# COMPUTE_CLUSTER0_ECC_AGGR register map
Vendor: Texas Instruments
Peripheral module from a debugger description file (folder J7VCL).
Registers are 32-bit, access not given, reset 0x0 unless marked. A register's access mark holds for its fields unless they carry their own. Offsets are as the file gives them; lines under a group give offsets from that group; [hi:lo] are bit positions; {n}, {i} and the like mark numbered series; 'fields as' and 'values as' point back to an identical list; <NAME> marks a mode.

## COMPUTE_CLUSTER0_ECC_AGGR
0x00 GIC_ECC_AGGR_REV ro reset 0x66A0EA00 — IP revision register.
  [31:0] REV — TI internal data. Identifies revision of peripheral.
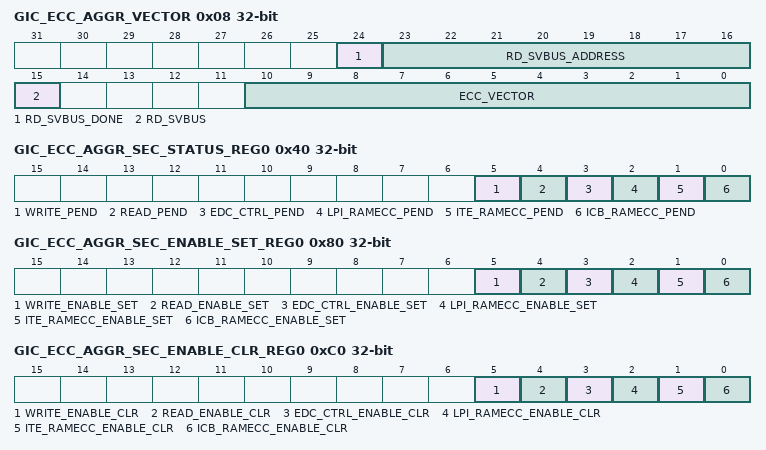
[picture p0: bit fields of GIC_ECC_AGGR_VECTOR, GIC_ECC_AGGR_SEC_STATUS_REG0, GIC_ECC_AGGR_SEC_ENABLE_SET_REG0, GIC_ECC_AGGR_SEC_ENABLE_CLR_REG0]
0x08 GIC_ECC_AGGR_VECTOR — ECC vector register.
  [24] RD_SVBUS_DONE — Status to indicate if read on serial VBUS is complete, write of any value will clear this bit. (access RW1C)
  [23:16] RD_SVBUS_ADDRESS rw — Read address
  [15] RD_SVBUS — Write 1 to trigger a read on the serial VBUS (access RW1S)
  [10:0] ECC_VECTOR rw — Value written to select the corresponding ECC RAM for control or status
0x0C GIC_ECC_AGGR_STAT ro reset 0x6 — Misc status register.
  [10:0] NUM_RAMS — Indicates the number of RAMs serviced by the ECC aggregator
0x3C GIC_ECC_AGGR_SEC_EOI_REG — EOI register. The EOI register is used to re-trigger the pulse interrupt signal to ensure that any nested interrupt events are serviced. The software interrupt handler must write to the EOI register at the end of the current interrupt processing routine, so that new events can re-trigger the pulse interrupt signal again. For level interrupt signals the EOI register is not functional and must not be used.
  [0] EOI_WR — EOI value (access RW1S)
0x40 GIC_ECC_AGGR_SEC_STATUS_REG0 — SEC interrupt status register 0.
  [5] WRITE_PEND — Interrupt pending status for write_pend (access RW1S)
  [4] READ_PEND — Interrupt pending status for read_pend (access RW1S)
  [3] EDC_CTRL_PEND — Interrupt pending status for edc_ctrl_pend (access RW1S)
  [2] LPI_RAMECC_PEND — Interrupt pending status for lpi_ramecc_pend (access RW1S)
  [1] ITE_RAMECC_PEND — Interrupt pending status for ite_ramecc_pend (access RW1S)
  [0] ICB_RAMECC_PEND — Interrupt pending status for icb_ramecc_pend (access RW1S)
0x80 GIC_ECC_AGGR_SEC_ENABLE_SET_REG0 — SEC interrupt enable set register 0.
  [5] WRITE_ENABLE_SET — Interrupt enable set for write_pend (access RW1S)
  [4] READ_ENABLE_SET — Interrupt enable set for read_pend (access RW1S)
  [3] EDC_CTRL_ENABLE_SET — Interrupt enable set for edc_ctrl_pend (access RW1S)
  [2] LPI_RAMECC_ENABLE_SET — Interrupt enable set for lpi_ramecc_pend (access RW1S)
  [1] ITE_RAMECC_ENABLE_SET — Interrupt enable set for ite_ramecc_pend (access RW1S)
  [0] ICB_RAMECC_ENABLE_SET — Interrupt enable set for icb_ramecc_pend (access RW1S)
0xC0 GIC_ECC_AGGR_SEC_ENABLE_CLR_REG0 — SEC interrupt enable clear register 0.
  [5] WRITE_ENABLE_CLR — Interrupt enable clear for write_pend (access RW1C)
  [4] READ_ENABLE_CLR — Interrupt enable clear for read_pend (access RW1C)
  [3] EDC_CTRL_ENABLE_CLR — Interrupt enable clear for edc_ctrl_pend (access RW1C)
  [2] LPI_RAMECC_ENABLE_CLR — Interrupt enable clear for lpi_ramecc_pend (access RW1C)
  [1] ITE_RAMECC_ENABLE_CLR — Interrupt enable clear for ite_ramecc_pend (access RW1C)
  [0] ICB_RAMECC_ENABLE_CLR — Interrupt enable clear for icb_ramecc_pend (access RW1C)
0x13C GIC_ECC_AGGR_DED_EOI_REG — DED EOI register. The EOI register is used to re-trigger the pulse interrupt signal to ensure that any nested interrupt events are serviced. The software interrupt handler must write to the EOI register at the end of the current interrupt processing routine, so that new events can re-trigger the pulse interrupt signal again. For level interrupt signals the EOI register is not functional and must not be used.
  [0] EOI_WR — EOI value (access RW1S)
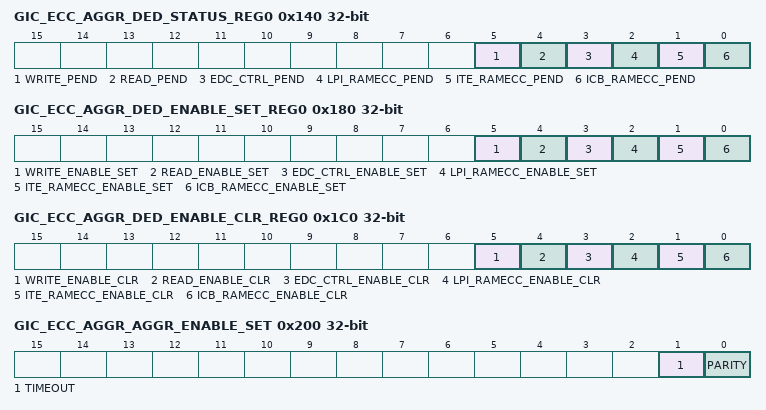
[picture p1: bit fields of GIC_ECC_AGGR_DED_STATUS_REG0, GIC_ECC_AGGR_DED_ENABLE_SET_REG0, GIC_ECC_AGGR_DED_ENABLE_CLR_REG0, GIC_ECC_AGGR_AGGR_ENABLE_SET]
0x140 GIC_ECC_AGGR_DED_STATUS_REG0 — DED interrupt status register 0.
  fields as GIC_ECC_AGGR_SEC_STATUS_REG0
0x180 GIC_ECC_AGGR_DED_ENABLE_SET_REG0 — DED interrupt enable set register 0.
  fields as GIC_ECC_AGGR_SEC_ENABLE_SET_REG0
0x1C0 GIC_ECC_AGGR_DED_ENABLE_CLR_REG0 — DED interrupt enable clear register 0.
  fields as GIC_ECC_AGGR_SEC_ENABLE_CLR_REG0
0x200 GIC_ECC_AGGR_AGGR_ENABLE_SET — AGGR interrupt enable set register.
  [1] TIMEOUT — Interrupt enable set for svbus timeout errors (access RW1S)
  [0] PARITY — Interrupt enable set for parity errors (access RW1S)
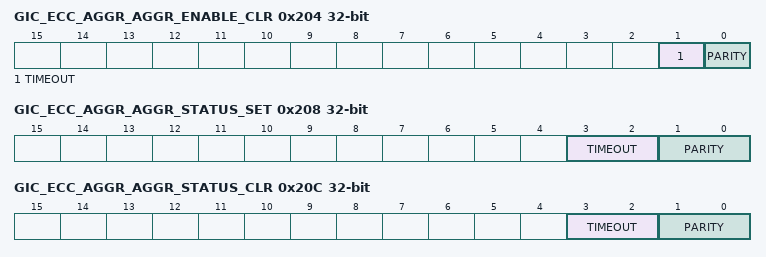
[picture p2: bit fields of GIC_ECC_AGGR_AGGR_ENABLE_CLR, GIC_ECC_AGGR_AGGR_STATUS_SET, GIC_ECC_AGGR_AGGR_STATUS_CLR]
0x204 GIC_ECC_AGGR_AGGR_ENABLE_CLR — AGGR interrupt enable clear register.
  [1] TIMEOUT — Interrupt enable clear for svbus timeout errors (access RW1C)
  [0] PARITY — Interrupt enable clear for parity errors (access RW1C)
0x208 GIC_ECC_AGGR_AGGR_STATUS_SET — AGGR interrupt status set register.
  [3:2] TIMEOUT — Interrupt status set for svbus timeout errors (access RWincr)
  [1:0] PARITY — Interrupt status set for parity errors (access RWincr)
0x20C GIC_ECC_AGGR_AGGR_STATUS_CLR — AGGR interrupt status clear register.
  [3:2] TIMEOUT — Interrupt status clear for svbus timeout errors (access RWdecr)
  [1:0] PARITY — Interrupt status clear for parity errors (access RWdecr)
